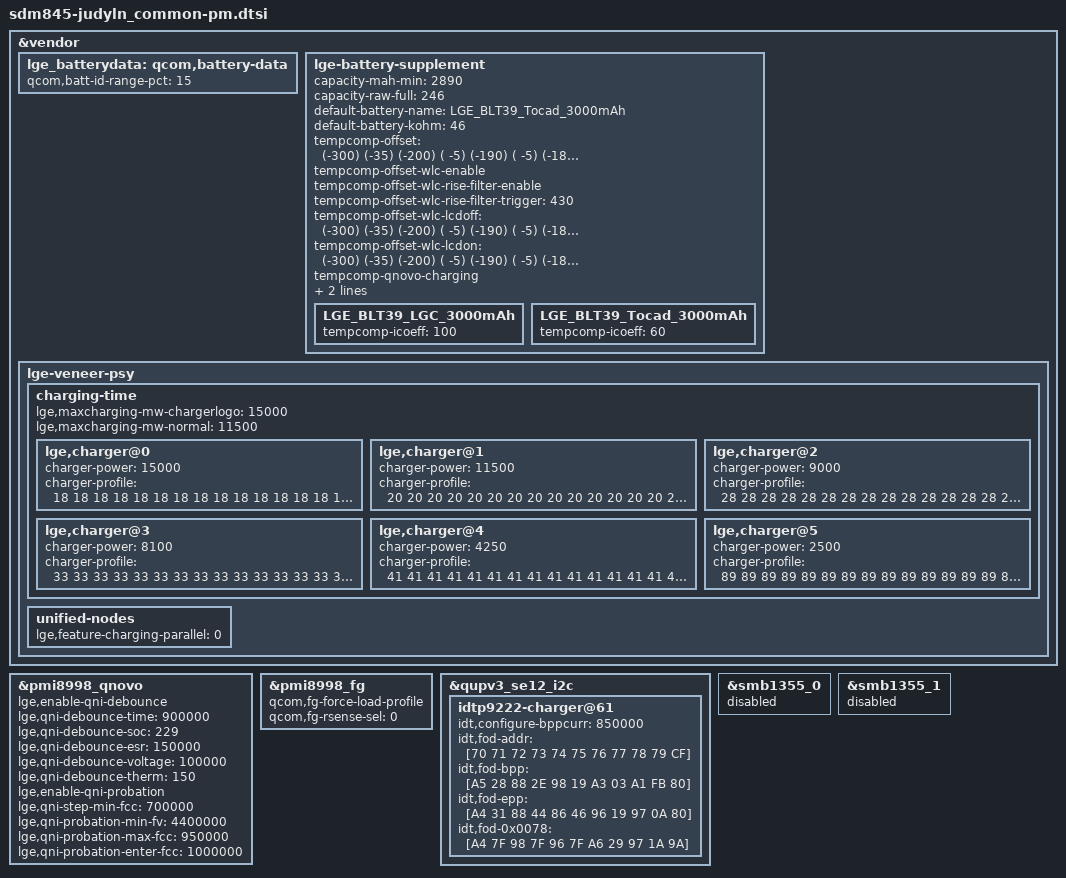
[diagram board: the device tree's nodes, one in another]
/* Copyright (c) 2017, The Linux Foundation. All rights reserved.
 *
 * This program is free software; you can redistribute it and/or modify
 * it under the terms of the GNU General Public License version 2 and
 * only version 2 as published by the Free Software Foundation.
 *
 * This program is distributed in the hope that it will be useful,
 * but WITHOUT ANY WARRANTY; without even the implied warranty of
 * MERCHANTABILITY or FITNESS FOR A PARTICULAR PURPOSE.  See the
 * GNU General Public License for more details.
 */

#include "../sdm845-judy_common/sdm845-judy_common-pm.dtsi"

&vendor {
	lge_batterydata: qcom,battery-data {
		qcom,batt-id-range-pct = <15>;
		#include "../../sdm845-battery/LGE_BLT39_LGC_3000mAh.dtsi"
		#include "../../sdm845-battery/LGE_BLT39_Tocad_3000mAh.dtsi"
	};

	lge-battery-supplement {
		capacity-mah-min = <2890>;
		capacity-raw-full = <246>;

		default-battery-name = "LGE_BLT39_Tocad_3000mAh";
		default-battery-kohm = <46>;

		/* format : (temp index) (temp delta) */
		tempcomp-offset = <
			(-300) (-35)
			(-200) ( -5)
			(-190) ( -5)
			(-180)    0
			(-170)    5
			(-160)   10
			(-150)   25
			(-100)   29
			( -50)   36
			    0    38
			   50    25
			  100    21
			  150    12
			  200     2
			  250  (-10)
			  300  (-22)
			  350  (-34)
			  400  (-41)
			  450  (-48)
			  500  (-52)
			  550  (-43)
			  600  (-34)
			  700  (-10)
			  800  (-10)
			  900  (-10)
		>;

		tempcomp-offset-wlc-enable;
		tempcomp-offset-wlc-rise-filter-enable;
		tempcomp-offset-wlc-rise-filter-trigger = <430>;
		tempcomp-offset-wlc-lcdoff = <
			(-300) (-35)
			(-200) ( -5)
			(-190) ( -5)
			(-180)    0
			(-170)    5
			(-160)   10
			(-150)   25
			(-100)   29
			( -50)   36
			    0    38
			   50    25
			  100    21
			  150    12
			  200     2
			  250  (-10)
			  300  (-20)
			  350  (-20)
			  400  (-10)
			  450  (-20)
			  500  (-10)
			  550  (0)
			  600  (10)
			  700  (10)
			  800  (10)
			  900  (10)
		>;

		tempcomp-offset-wlc-lcdon = <
			(-300) (-35)
			(-200) ( -5)
			(-190) ( -5)
			(-180)    0
			(-170)    5
			(-160)   10
			(-150)   25
			(-100)   29
			( -50)   36
			    0    38
			   50    25
			  100    21
			  150    12
			  200     2
			  250  (-10)
			  300  (-22)
			  350  (-34)
			  400  (-41)
			  450  (-51)
			  500  (-55)
			  550  (-46)
			  600  (-34)
			  700  (-10)
			  800  (-10)
			  900  (-10)
		>;

		tempcomp-qnovo-charging;
		lg-monotonic-soc-enable;

		tempcomp-icoeff = <100>;
		/* overriding by battery type */
		LGE_BLT39_LGC_3000mAh {
			tempcomp-icoeff = <100>;
		};
		LGE_BLT39_Tocad_3000mAh {
			tempcomp-icoeff = <60>;
		};
	};

	lge-veneer-psy {
		charging-time {
			#address-cells = <1>;
			#size-cells = <0>;

			lge,maxcharging-mw-chargerlogo = <15000>;
			lge,maxcharging-mw-normal = <11500>;

			lge,charger@0 {		//  fast charger: 9000mV * 1660mA or 5000mV * 3000mA
				charger-power = <15000>;
				charger-profile = <
					18  18  18  18  18  18  18  18  18  18  18  18  18  18  18  18
					18  18  18  18  18  18  18  18  18  18  18  18  18  18  18  18
					18  18  18  18  18  18  18  18  18  18  18  18  18  18  18  18
					18  18  18  18  18  18  18  18  18  18  18  18  18  18  18  18
					18  18  18  18  18  18  18  18  18  18  18  18  18  18  18  18
					18  18  18  18  18  18  18  18  18  18  18  18  18  18  18  18
					18  18  18  18  18  18  18  18  18  18  18  18  18  18  18  18
					18  18  18  18  18  18  18  18  18  18  18  18  18  18  18  18
					18  18  18  18  18  18  18  18  18  18  18  18  18  18  18  18
					18  18  18  18  18  18  18  18  18  18  18  21  21  21  21  21
					21  21  21  21  21  21  21  21  25  25  25  25  25  25  25  25
					25  25  25  25  25  25  25  25  25  25  25  25  25  29  29  29
					29  29  29  29  29  29  29  29  29  29  29  29  33  33  33  33
					33  33  33  33  33  35  35  45  45  45  45  45  45  45  45  45
					45  54  54  54  54  54  54  54  58  52  53  54  55  59  62  68
					74  80  85  93  99 108 108 108 108 108 108 108 108 108 108 108
				>;
			};
			lge,charger@1 {		//  power-on fast charger: 2.3A * 4.0V / 80% = 11.5W
				charger-power = <11500>;
				charger-profile = <
					20  20  20  20  20  20  20  20  20  20  20  20  20  20  20  20
					20  20  20  20  20  20  20  20  20  20  20  20  20  20  20  20
					20  20  20  20  20  20  20  20  20  20  20  20  20  20  20  20
					20  20  20  20  20  20  20  20  20  20  20  20  20  20  20  20
					20  20  20  20  20  20  20  20  20  20  20  20  20  20  20  20
					20  20  20  20  20  20  20  20  20  20  20  20  20  20  20  20
					20  20  20  20  20  20  20  20  20  20  20  20  20  20  20  20
					20  20  20  20  20  20  20  20  20  20  20  20  20  20  20  20
					20  20  20  20  20  20  20  20  20  20  20  20  20  20  20  20
					20  20  20  20  20  20  20  20  20  20  20  20  20  20  20  20
					20  20  20  20  20  20  20  20  24  24  24  24  24  24  24  24
					24  24  24  24  24  24  24  24  24  24  24  24  24  28  28  28
					28  28  28  28  28  28  28  28  28  28  28  28  31  31  31  31
					31  31  31  31  31  34  34  43  43  43  43  43  43  43  43  43
					43  52  52  52  52  52  52  52  55  52  53  54  55  59  62  68
					74  80  85  93  99 108 108 108 108 108 108 108 108 108 108 108
				>;
			};
			lge,charger@2 {		//  dcp charger: 5000mV * 1800mA = 9W
				charger-power = <9000>;
				charger-profile = <
					28  28  28  28  28  28  28  28  28  28  28  28  28  28  28  28
					28  28  28  29  29  29  29  29  29  29  29  29  29  29  29  29
					29  29  29  29  29  29  29  29  29  29  29  29  29  29  29  29
					29  29  29  29  29  29  29  29  29  29  29  29  29  29  29  29
					29  29  29  29  30  30  30  30  30  30  30  30  30  30  30  30
					30  30  30  30  30  30  30  30  30  30  30  30  30  30  30  30
					30  30  30  30  30  30  30  30  30  30  30  30  30  30  30  30
					30  31  31  31  31  31  31  31  31  31  31  31  31  31  31  31
					31  31  31  31  31  31  31  31  31  31  31  31  31  31  31  31
					31  31  31  31  31  31  31  31  31  31  31  31  32  32  32  32
					32  32  32  32  32  32  32  32  32  32  32  32  32  32  32  32
					32  32  32  32  32  32  32  32  32  32  32  32  32  32  32  32
					32  32  32  33  33  33  33  33  33  33  33  33  34  34  34  35
					35  35  36  36  37  37  37  36  38  39  38  39  39  40  42  43
					44  45  46  47  47  47  48  50  51  52  53  54  55  59  62  68
					74  80  85  93  99 108 108 108 108 108 108 108 108 108 108 108
				>;
			};
			lge,charger@3 {		// EPP wireless charger: 9000mV * 900mA = 8.1W
				charger-power = <8100>;
				charger-profile = <
					33  33  33  33  33  33  33  33  33  33  33  33  33  33  33  33
					33  33  33  33  33  33  33  33  33  33  33  33  33  33  33  33
					33  33  33  33  33  33  33  33  33  33  33  33  33  33  33  33
					33  33  33  33  33  33  33  33  33  33  33  33  33  33  33  33
					33  33  33  33  33  33  33  33  33  33  33  33  33  33  33  33
					33  33  33  33  33  33  33  33  33  33  33  33  33  33  33  33
					33  33  33  33  33  33  33  33  33  34  34  34  34  34  34  34
					34  34  34  34  34  34  34  34  34  34  34  34  34  34  34  34
					34  34  34  34  34  34  34  34  34  34  34  34  34  34  34  34
					34  34  34  34  34  34  35  35  35  35  35  35  35  35  35  35
					35  35  35  35  35  35  35  35  35  35  35  35  35  35  35  35
					35  35  35  35  35  35  35  35  35  35  35  35  35  35  35  35
					36  36  36  36  36  36  36  36  36  36  36  36  36  36  36  36
					36  37  37  37  38  38  39  40  41  42  43  45  46  47  48  50
					51  53  52  52  52  52  52  52  52  52  53  54  55  59  62  68
					74  80  85  93  99 108 108 108 108 108 108 108 108 108 108 108
				>;
			};
			lge,charger@4 {		// BPP wireless charger: 5000mV * 850mA = 4.25W
				charger-power = <4250>;
				charger-profile = <
					41  41  41  41  41  41  41  41  41  41  41  41  41  41  41  41
					42  42  42  42  42  42  42  42  42  42  42  42  42  42  42  42
					42  42  42  42  42  42  42  42  42  42  43  43  43  43  43  43
					43  43  43  43  43  43  43  43  43  43  43  43  43  43  43  43
					43  43  44  44  44  44  44  44  44  44  44  44  44  44  44  44
					44  44  44  44  44  44  44  44  44  44  44  45  45  45  45  45
					45  45  45  45  45  45  45  45  45  45  45  45  45  45  45  45
					46  46  46  46  46  46  46  46  46  46  46  46  46  46  46  46
					46  46  46  46  46  46  47  47  47  47  47  47  47  47  47  47
					47  47  47  47  47  47  47  47  47  47  47  48  48  48  48  48
					48  48  48  48  48  48  48  48  48  48  48  48  48  48  48  49
					49  49  49  49  49  49  49  49  49  49  49  49  49  49  49  49
					49  49  50  50  50  50  50  50  50  50  50  50  50  50  50  50
					50  50  50  51  51  51  51  51  51  51  51  51  51  51  51  51
					51  51  51  51  51  52  52  52  52  52  53  54  55  59  62  68
					74  80  85  93  99 108 108 108 108 108 108 108 108 108 108 108
				>;
			};
			lge,charger@5 {		// SDP: 5000mV * 500mA = 2.5W
				charger-power = <2500>;
				charger-profile = <
					89  89  89  89  89  89  89  89  89  89  89  89  89  89  89  89
					89  89  89  89  89  89  89  89  89  89  89  89  89  89  89  89
					89  89  89  89  89  89  89  89  89  89  89  89  89  89  89  89
					89  89  89  89  89  89  89  89  89  89  89  89  89  89  89  89
					89  89  89  89  89  89  89  89  89  89  89  89  89  89  89  89
					89  89  89  89  89  89  89  89  89  89  89  89  89  89  89  89
					89  89  89  89  89  89  89  89  89  89  89  89  89  89  89  89
					89  89  89  89  89  89  89  89  89  89  89  89  89  89  89  89
					89  89  89  89  89  89  89  89  89  89  89  89  89  89  89  89
					89  89  89  89  89  89  89  89  89  89  89  89  89  89  89  89
					89  89  89  89  89  89  89  89  89  89  89  89  89  89  89  89
					89  89  89  89  89  89  89  89  89  89  89  89  89  89  89  89
					89  89  89  89  89  89  89  89  89  89  89  89  89  89  89  89
					89  89  89  89  89  89  89  89  89  89  89  89  89  89  89  89
					89  89  89  89  89  89  89  89  89  89  89  89  89  89  89  89
					89  89  89  93  99 108 108 108 108 108 108 108 108 108 108 108
				>;
			};
		};

		unified-nodes {
			lge,feature-charging-parallel = <0>;
		};
	};
};

&pmi8998_qnovo {
	lge,enable-qni-debounce;
	lge,qni-debounce-time = <900000>;
	lge,qni-debounce-soc = <229>;
	lge,qni-debounce-esr = <150000>;
	lge,qni-debounce-voltage = <100000>;
	lge,qni-debounce-therm = <150>;

	lge,enable-qni-probation;
	lge,qni-step-min-fcc = <700000>;
	lge,qni-probation-min-fv = <4400000>;
	lge,qni-probation-max-fcc = <950000>;
	lge,qni-probation-enter-fcc = <1000000>;
};

&pmi8998_fg {
	qcom,fg-force-load-profile;
	qcom,fg-rsense-sel = <0>;
};

&qupv3_se12_i2c {
	idtp9222-charger@61 {
		idt,configure-bppcurr = <850000>;

		// FOD parameters
		idt,fod-addr   = [70 71 72 73 74 75 76 77 78 79 CF];
		idt,fod-bpp    = [A5 28 88 2E 98 19 A3 03 A1 FB 80];
		idt,fod-epp    = [A4 31 88 44 86 46 96 19 97 0A 80];
		idt,fod-0x0078 = [A4 7F 98 7F 96 7F A6 29 97 1A 9A];
	};
};

&smb1355_0 {
	status = "disabled";
};

&smb1355_1 {
	status = "disabled";
};
